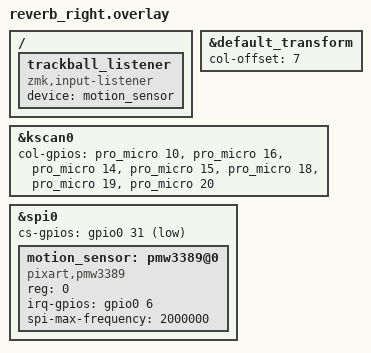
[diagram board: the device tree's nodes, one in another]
/*
 * Copyright (c) 2024 Noah Boggs 
 *
 * SPDX-License-Identifier: MIT
 */

#include "reverb.dtsi" 

&default_transform {
    col-offset = <7>;
};

/* For PX.Y pins that don't have an alias, for example P1.13 use &gpio1 13*/
&kscan0 {
    col-gpios
        = <&pro_micro 10 GPIO_ACTIVE_HIGH>
        , <&pro_micro 16 GPIO_ACTIVE_HIGH>
        , <&pro_micro 14 GPIO_ACTIVE_HIGH>
        , <&pro_micro 15 GPIO_ACTIVE_HIGH>
        , <&pro_micro 18 GPIO_ACTIVE_HIGH>
        , <&pro_micro 19 GPIO_ACTIVE_HIGH>
        , <&pro_micro 20 GPIO_ACTIVE_HIGH>
        ;
};

// https://www.tindie.com/products/citizenjoe/pmw3389-motion-sensor/#specs
&spi0 {
    cs-gpios = <&gpio0 31 GPIO_ACTIVE_LOW>;  // Chip select 0 for pmw3389
    motion_sensor: pmw3389@0 {
        compatible = "pixart,pmw3389";
        status = "okay";
        reg = <0>;
        irq-gpios = <&gpio0 6 GPIO_ACTIVE_HIGH>; //<&gpio0 6 (GPIO_ACTIVE_LOW | GPIO_PULL_UP)>;
        spi-max-frequency = <2000000>; // 2MHz
   };
};

/ {
  trackball_listener {
    compatible = "zmk,input-listener";
    device = <&motion_sensor>;
  };
};

